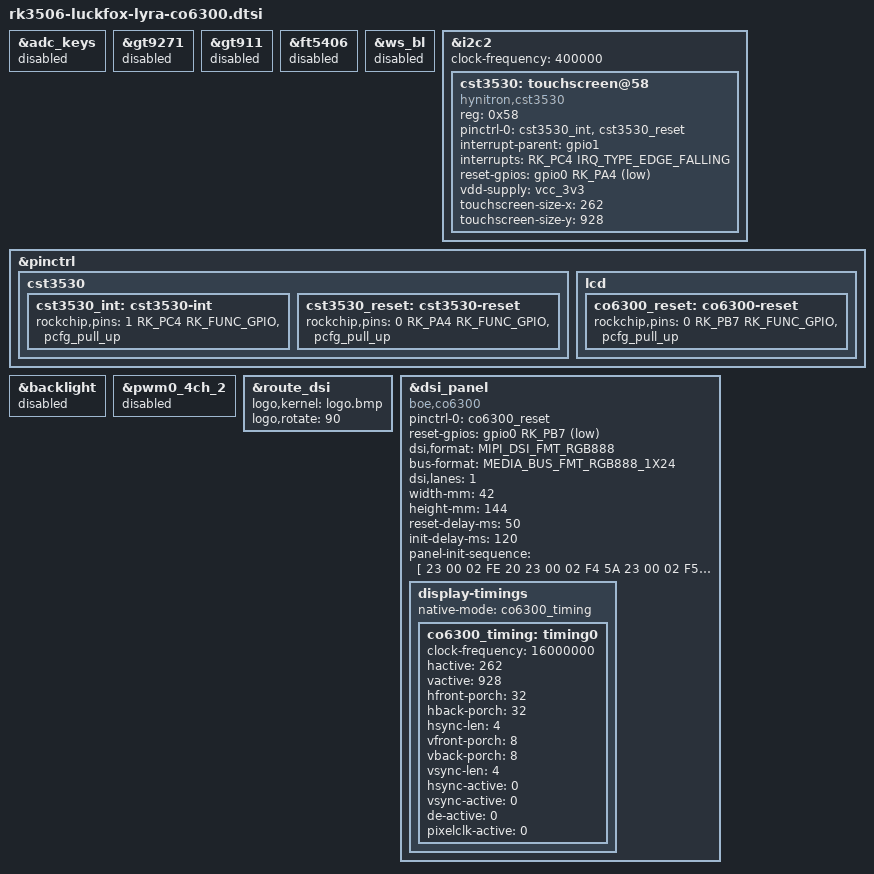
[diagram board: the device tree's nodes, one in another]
// SPDX-License-Identifier: (GPL-2.0+ OR MIT)
/*
 * Luckfox Lyra CO6300 AMOLED variant.
 *
 * The board hardware remains defined by the generic Lyra Ultra DTSI. This
 * file only replaces its example panel with the 272x928 CO6300 module.
 */
/dts-v1/;

#include <dt-bindings/display/media-bus-format.h>
#include <dt-bindings/interrupt-controller/irq.h>
#include "rk3506-luckfox-lyra-ultra.dtsi"

/* Replace the example touch controllers with the module's CST3530. */
&adc_keys {
	status = "disabled";
};

&gt9271 {
	status = "disabled";
};

&gt911 {
	status = "disabled";
};

&ft5406 {
	status = "disabled";
};

&ws_bl {
	status = "disabled";
};

&i2c2 {
	clock-frequency = <400000>;

	cst3530: touchscreen@58 {
		compatible = "hynitron,cst3530";
		reg = <0x58>;
		pinctrl-names = "default";
		pinctrl-0 = <&cst3530_int &cst3530_reset>;
		interrupt-parent = <&gpio1>;
		interrupts = <RK_PC4 IRQ_TYPE_EDGE_FALLING>;
		reset-gpios = <&gpio0 RK_PA4 GPIO_ACTIVE_LOW>;
		vdd-supply = <&vcc_3v3>;
		touchscreen-size-x = <262>;
		touchscreen-size-y = <928>;
		status = "okay";
	};
};

&pinctrl {
	cst3530 {
		cst3530_int: cst3530-int {
			rockchip,pins = <1 RK_PC4 RK_FUNC_GPIO &pcfg_pull_up>;
		};

		cst3530_reset: cst3530-reset {
			rockchip,pins = <0 RK_PA4 RK_FUNC_GPIO &pcfg_pull_up>;
		};
	};

	lcd {
		co6300_reset: co6300-reset {
			rockchip,pins = <0 RK_PB7 RK_FUNC_GPIO &pcfg_pull_up>;
		};
	};
};

/* The CO6300 uses DCS brightness, and the PWM pin is wired to reset. */
&backlight {
	status = "disabled";
};

&pwm0_4ch_2 {
	status = "disabled";
};

&route_dsi {
	logo,kernel = "logo.bmp";
	logo,rotate = <90>;
};

&dsi_panel {
	/delete-property/ backlight;

	compatible = "boe,co6300";
	pinctrl-names = "default";
	pinctrl-0 = <&co6300_reset>;
	reset-gpios = <&gpio0 RK_PB7 GPIO_ACTIVE_LOW>;
	dsi,format = <MIPI_DSI_FMT_RGB888>;
	bus-format = <MEDIA_BUS_FMT_RGB888_1X24>;
	dsi,lanes = <1>;
	width-mm = <42>;
	height-mm = <144>;

	/* U-Boot uses this sequence; Linux has a native panel driver. */
	reset-delay-ms = <50>;
	init-delay-ms = <120>;
	panel-init-sequence = [
		23 00 02 FE 20
		23 00 02 F4 5A
		23 00 02 F5 59
		23 00 02 FE 80
		23 00 02 03 00
		23 00 02 FE 00
		15 00 02 35 00
		15 00 02 3A 77
		15 00 02 36 00
		39 00 05 2A 00 00 01 05
		39 00 05 2B 00 00 03 9F
		15 00 02 53 20
		15 00 02 51 80
		15 00 02 63 FF
		05 3C 01 11
		05 00 01 29
		15 00 02 51 80
		15 00 02 58 07
	];
	/delete-node/ display-timings;

	display-timings {
		native-mode = <&co6300_timing>;
		co6300_timing: timing0 {
			clock-frequency = <16000000>;
			hactive = <262>;
			vactive = <928>;
			hfront-porch = <32>;
			hback-porch = <32>;
			hsync-len = <4>;
			vfront-porch = <8>;
			vback-porch = <8>;
			vsync-len = <4>;
			hsync-active = <0>;
			vsync-active = <0>;
			de-active = <0>;
			pixelclk-active = <0>;
		};
	};
};
